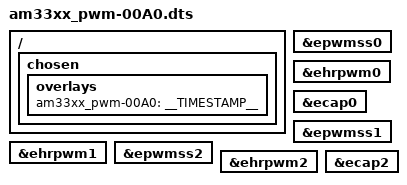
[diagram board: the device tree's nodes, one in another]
/*
 * Copyright (C) 2013 CircuitCo
 * Copyright (C) 2013 Texas Instruments
 *
 * This program is free software; you can redistribute it and/or modify
 * it under the terms of the GNU General Public License version 2 as
 * published by the Free Software Foundation.
 */
/dts-v1/;
/plugin/;

/ {
	/*
	 * Helper to show loaded overlays under: /proc/device-tree/chosen/overlays/
	 */
	fragment@0 {
		target-path="/";
		__overlay__ {

			chosen {
				overlays {
					am33xx_pwm-00A0 = __TIMESTAMP__;
				};
			};
		};
	};

	fragment@1 {
		target = <&epwmss0>;
		__overlay__ {
			status = "okay";
		};
	};

	fragment@2 {
		target = <&ehrpwm0>;
		__overlay__ {
			status = "okay";
		};
	};

	fragment@3 {
		target = <&ecap0>;
		__overlay__ {
			status = "okay";
		};
	};

	fragment@4 {
		target = <&epwmss1>;
		__overlay__ {
			status = "okay";
		};
	};

	fragment@5 {
		target = <&ehrpwm1>;
		__overlay__ {
			status = "okay";
		};
	};

	fragment@6 {
		target = <&epwmss2>;
		__overlay__ {
			status = "okay";
		};
	};

	fragment@7 {
		target = <&ehrpwm2>;
		__overlay__ {
			status = "okay";
		};
	};

	fragment@8 {
		target = <&ecap2>;
		__overlay__ {
			status = "okay";
		};
	};
};
